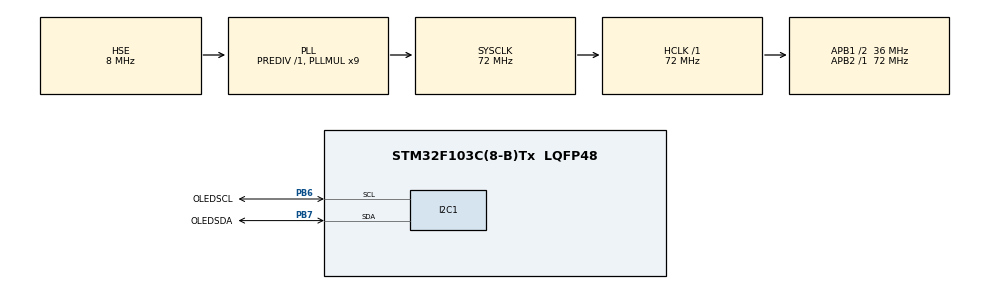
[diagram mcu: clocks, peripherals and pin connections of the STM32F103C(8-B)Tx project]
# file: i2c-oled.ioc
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Mcu.Family=STM32F1
Mcu.Name=STM32F103C(8-B)Tx
Mcu.Package=LQFP48
NVIC.PriorityGroup=NVIC_PRIORITYGROUP_4
PB6.GPIO_Label=OLEDSCL
PB6.Mode=I2C
PB6.Signal=I2C1_SCL
PB7.GPIO_Label=OLEDSDA
PB7.Mode=I2C
PB7.Signal=I2C1_SDA
PD0-OSC_IN.Mode=HSE-External-Oscillator
PD0-OSC_IN.Signal=RCC_OSC_IN
PD1-OSC_OUT.Mode=HSE-External-Oscillator
PD1-OSC_OUT.Signal=RCC_OSC_OUT
ProjectManager.HeapSize=0x200
ProjectManager.StackSize=0x400
ProjectManager.TargetToolchain=STM32CubeIDE
RCC.AHBFreq_Value=72000000
RCC.APB1CLKDivider=RCC_HCLK_DIV2
RCC.APB1Freq_Value=36000000
RCC.APB1TimFreq_Value=72000000
RCC.APB2Freq_Value=72000000
RCC.APB2TimFreq_Value=72000000
RCC.HCLKFreq_Value=72000000
RCC.PLLMUL=RCC_PLL_MUL9
RCC.PLLSourceVirtual=RCC_PLLSOURCE_HSE
RCC.SYSCLKFreq_VALUE=72000000
RCC.SYSCLKSource=RCC_SYSCLKSOURCE_PLLCLK
RCC.USBFreq_Value=72000000
VP_SYS_VS_ND.Mode=No_Debug
board=custom

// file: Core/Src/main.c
/* USER CODE BEGIN Header */
/**
  ******************************************************************************
  * @file           : main.c
  * @brief          : Main program body
  ******************************************************************************
  * @attention
  *
  * Copyright (c) 2023 STMicroelectronics.
  * All rights reserved.
  *
  * This software is licensed under terms that can be found in the LICENSE file
  * in the root directory of this software component.
  * If no LICENSE file comes with this software, it is provided AS-IS.
  *
  ******************************************************************************
  */
/* USER CODE END Header */
#include "main.h"
#include "i2c.h"
#include "gpio.h"

/* USER CODE BEGIN Includes */
#include "OLED.h"
#include "KUNKUN.h"
/* USER CODE END Includes */

void SystemClock_Config(void);

int main(void)
{

  /* MCU Configuration--------------------------------------------------------*/

  /* Reset of all peripherals, Initializes the Flash interface and the Systick. */
  HAL_Init();

  /* Configure the system clock */
  SystemClock_Config();

  /* Initialize all configured peripherals */
  MX_GPIO_Init();
  MX_I2C1_Init();
  /* USER CODE BEGIN 2 */
  OLED_Init();
  OLED_Fill(0xff);
  HAL_Delay(500);
  OLED_Fill(0x00);
  OLED_ShowString(2, 4, "OLED START");
  HAL_Delay(1000);
  OLED_Fill(0x00);
  /* USER CODE END 2 */

  /* Infinite loop */
  while (1)
  {
	  Show_Bmp(0,0,64,64,(unsigned char*)BMP1); HAL_Delay(50);
	  			Show_Bmp(0,0,64,64,(unsigned char*)BMP2); HAL_Delay(50);
	  			Show_Bmp(0,0,64,64,(unsigned char*)BMP3); HAL_Delay(50);
	  			Show_Bmp(0,0,64,64,(unsigned char*)BMP4); HAL_Delay(50);
	  			Show_Bmp(0,0,64,64,(unsigned char*)BMP5); HAL_Delay(50);
	  			Show_Bmp(0,0,64,64,(unsigned char*)BMP6); HAL_Delay(50);
	  			Show_Bmp(0,0,64,64,(unsigned char*)BMP7); HAL_Delay(50);
	  			Show_Bmp(0,0,64,64,(unsigned char*)BMP8); HAL_Delay(50);
	  			Show_Bmp(0,0,64,64,(unsigned char*)BMP9); HAL_Delay(50);
	  			Show_Bmp(0,0,64,64,(unsigned char*)BMP10); HAL_Delay(50);
	  			Show_Bmp(0,0,64,64,(unsigned char*)BMP11); HAL_Delay(50);
	  			Show_Bmp(0,0,64,64,(unsigned char*)BMP12); HAL_Delay(50);
	  			Show_Bmp(0,0,64,64,(unsigned char*)BMP13); HAL_Delay(50);
	  			Show_Bmp(0,0,64,64,(unsigned char*)BMP14); HAL_Delay(50);
	  			Show_Bmp(0,0,64,64,(unsigned char*)BMP15); HAL_Delay(50);
	  			Show_Bmp(0,0,64,64,(unsigned char*)BMP16); HAL_Delay(50);
	  			Show_Bmp(0,0,64,64,(unsigned char*)BMP17); HAL_Delay(50);
	  			Show_Bmp(0,0,64,64,(unsigned char*)BMP18); HAL_Delay(50);
	  			Show_Bmp(0,0,64,64,(unsigned char*)BMP19); HAL_Delay(50);
	  			Show_Bmp(0,0,64,64,(unsigned char*)BMP20); HAL_Delay(50);
	  			Show_Bmp(0,0,64,64,(unsigned char*)BMP21); HAL_Delay(50);
	  			Show_Bmp(0,0,64,64,(unsigned char*)BMP22); HAL_Delay(50);
	  			Show_Bmp(0,0,64,64,(unsigned char*)BMP23); HAL_Delay(50);
	  			Show_Bmp(0,0,64,64,(unsigned char*)BMP24); HAL_Delay(50);
	  			Show_Bmp(0,0,64,64,(unsigned char*)BMP25); HAL_Delay(50);
	  			Show_Bmp(0,0,64,64,(unsigned char*)BMP26); HAL_Delay(50);
	  			Show_Bmp(0,0,64,64,(unsigned char*)BMP27); HAL_Delay(50);
	  			Show_Bmp(0,0,64,64,(unsigned char*)BMP28); HAL_Delay(50);
	  			Show_Bmp(0,0,64,64,(unsigned char*)BMP29); HAL_Delay(50);
	  			Show_Bmp(0,0,64,64,(unsigned char*)BMP30); HAL_Delay(50);
	  			Show_Bmp(0,0,64,64,(unsigned char*)BMP31); HAL_Delay(50);
	  			Show_Bmp(0,0,64,64,(unsigned char*)BMP32); HAL_Delay(50);
	  			Show_Bmp(0,0,64,64,(unsigned char*)BMP33); HAL_Delay(50);
	  			Show_Bmp(0,0,64,64,(unsigned char*)BMP34); HAL_Delay(50);
	  			Show_Bmp(0,0,64,64,(unsigned char*)BMP35); HAL_Delay(50);
	  			Show_Bmp(0,0,64,64,(unsigned char*)BMP36); HAL_Delay(50);
	  			Show_Bmp(0,0,64,64,(unsigned char*)BMP37); HAL_Delay(50);
	  			Show_Bmp(0,0,64,64,(unsigned char*)BMP38); HAL_Delay(50);
  }
}

void SystemClock_Config(void)
{
  RCC_OscInitTypeDef RCC_OscInitStruct = {0};
  RCC_ClkInitTypeDef RCC_ClkInitStruct = {0};

  /** Initializes the RCC Oscillators according to the specified parameters
  * in the RCC_OscInitTypeDef structure.
  */
  RCC_OscInitStruct.OscillatorType = RCC_OSCILLATORTYPE_HSE;
  RCC_OscInitStruct.HSEState = RCC_HSE_ON;
  RCC_OscInitStruct.HSEPredivValue = RCC_HSE_PREDIV_DIV1;
  RCC_OscInitStruct.HSIState = RCC_HSI_ON;
  RCC_OscInitStruct.PLL.PLLState = RCC_PLL_ON;
  RCC_OscInitStruct.PLL.PLLSource = RCC_PLLSOURCE_HSE;
  RCC_OscInitStruct.PLL.PLLMUL = RCC_PLL_MUL9;
  if (HAL_RCC_OscConfig(&RCC_OscInitStruct) != HAL_OK)
  {
    Error_Handler();
  }

  /** Initializes the CPU, AHB and APB buses clocks
  */
  RCC_ClkInitStruct.ClockType = RCC_CLOCKTYPE_HCLK|RCC_CLOCKTYPE_SYSCLK
                              |RCC_CLOCKTYPE_PCLK1|RCC_CLOCKTYPE_PCLK2;
  RCC_ClkInitStruct.SYSCLKSource = RCC_SYSCLKSOURCE_PLLCLK;
  RCC_ClkInitStruct.AHBCLKDivider = RCC_SYSCLK_DIV1;
  RCC_ClkInitStruct.APB1CLKDivider = RCC_HCLK_DIV2;
  RCC_ClkInitStruct.APB2CLKDivider = RCC_HCLK_DIV1;

  if (HAL_RCC_ClockConfig(&RCC_ClkInitStruct, FLASH_LATENCY_2) != HAL_OK)
  {
    Error_Handler();
  }
}

void Error_Handler(void)
{
  __disable_irq();
  while (1)
  {
  }
}
